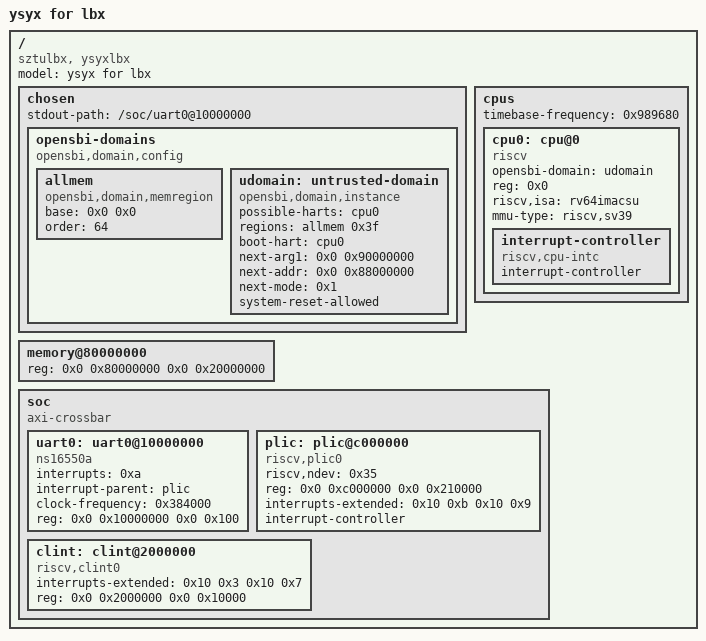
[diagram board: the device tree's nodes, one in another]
/dts-v1/;

/ {
	#address-cells = <0x2>;
	#size-cells = <0x2>;
	compatible = "sztulbx, ysyxlbx";
	model = "ysyx for lbx";

	chosen {
		stdout-path = "/soc/uart0@10000000";
        opensbi-domains {  /* 定义opensbi-domains描述节点 */
		    compatible = "opensbi,domain,config"; /* 节点名称 */

            // tmem: tmem {   /* 定义内存节点 */
            //     compatible = "opensbi,domain,memregion";  /* 节点名称 */
            //     base = <0x0 0xb0000000>; /* 起始地址注意64位地址哦 */
            //     order = <28>; /* 内存大小即size=2^28 */
            // };

            // tuart: tuart {  /* 定义mmio节点 */
            //     compatible = "opensbi,domain,memregion";  /* 节点名称 */
            //     base = <0x0 0x10002000>; /* 起始地址 */
            //     order = <8>; /* size=2^8 */
            //     mmio;  /* mmio属性 */
            //     devices = <&uart2>; /* 关联到设备节点上 */
            // };

		    allmem: allmem { /* 定义内存节点，这个节点保护所有地址 */
		        compatible = "opensbi,domain,memregion";
		        base = <0x0 0x0>;
		        order = <64>;
		    };

            // tdomain: trusted-domain { /* 定义domian节点 */
            //     compatible = "opensbi,domain,instance";  /* 节点名称 */
            //     possible-harts = <&cpu7>; /* dumian中允许使用的cpu core */
            //     regions = <&tmem 0x7>, <&tuart 0x7>, <&allmem 0x7>;/* 各个内存/mmio区域的权限，3bit读写运行权限 0x7拥有全部权限 */
            //     boot-hart = <&cpu7>; /* domian中用于boot的core */
            //     next-arg1 = <0x0 0x00000000>; /* 下级程序的参数 */
		    //     next-addr = <0x0 0xb0000000>; /* 下级程序的起始地址 */
		    //     next-mode = <0x0>; /* 下级程序的允许模式 0为U模式，1为S模式 */
            //     system-reset-allowed; /* 允许复位 */
            // };

		    udomain: untrusted-domain {
		        compatible = "opensbi,domain,instance";
		        possible-harts = <&cpu0>;
		        regions = <&allmem 0x3f>;
		    	boot-hart = <&cpu0>;
		        next-arg1 = <0x0 0x90000000>;
		        next-addr = <0x0 0x88000000>;
		        next-mode = <0x1>;
		        system-reset-allowed;
		    };
        };
	};

	memory@80000000 {
		device_type = "memory";
		reg = <0x0 0x80000000 0x0 0x20000000>;
	};

	cpus {
		#address-cells = <0x1>;
		#size-cells = <0x0>;
		timebase-frequency = <0x989680>;

		cpu0: cpu@0 {
			device_type = "cpu";
            opensbi-domain = <&udomain>;
			reg = <0x0>;
			status = "okay";
			compatible = "riscv";
			riscv,isa = "rv64imacsu";
			mmu-type = "riscv,sv39";

			interrupt-controller {
				#interrupt-cells = <0x1>;
				interrupt-controller;
				compatible = "riscv,cpu-intc";
                phandle = <0x10>;
			};
		};
	};

	soc {
		#address-cells = <0x2>;
		#size-cells = <0x2>;
		compatible = "axi-crossbar";
		ranges;

		uart0: uart0@10000000 {
			interrupts = <0xa>;
			interrupt-parent = <&plic>;
			clock-frequency = <0x384000>;
			reg = <0x0 0x10000000 0x0 0x100>;
			compatible = "ns16550a";
		};

		plic: plic@c000000 {
			riscv,ndev = <0x35>;
			reg = <0x0 0xc000000 0x0 0x210000>;
			interrupts-extended = <0x10 0xb 0x10 0x9>;
			interrupt-controller;
			compatible = "riscv,plic0";
			#interrupt-cells = <0x1>;
			#address-cells = <0x0>;
		};

		clint: clint@2000000 {
			interrupts-extended = <0x10 0x3 0x10 0x7>;
			reg = <0x0 0x2000000 0x0 0x10000>;
			compatible = "riscv,clint0";
		};
	};
};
